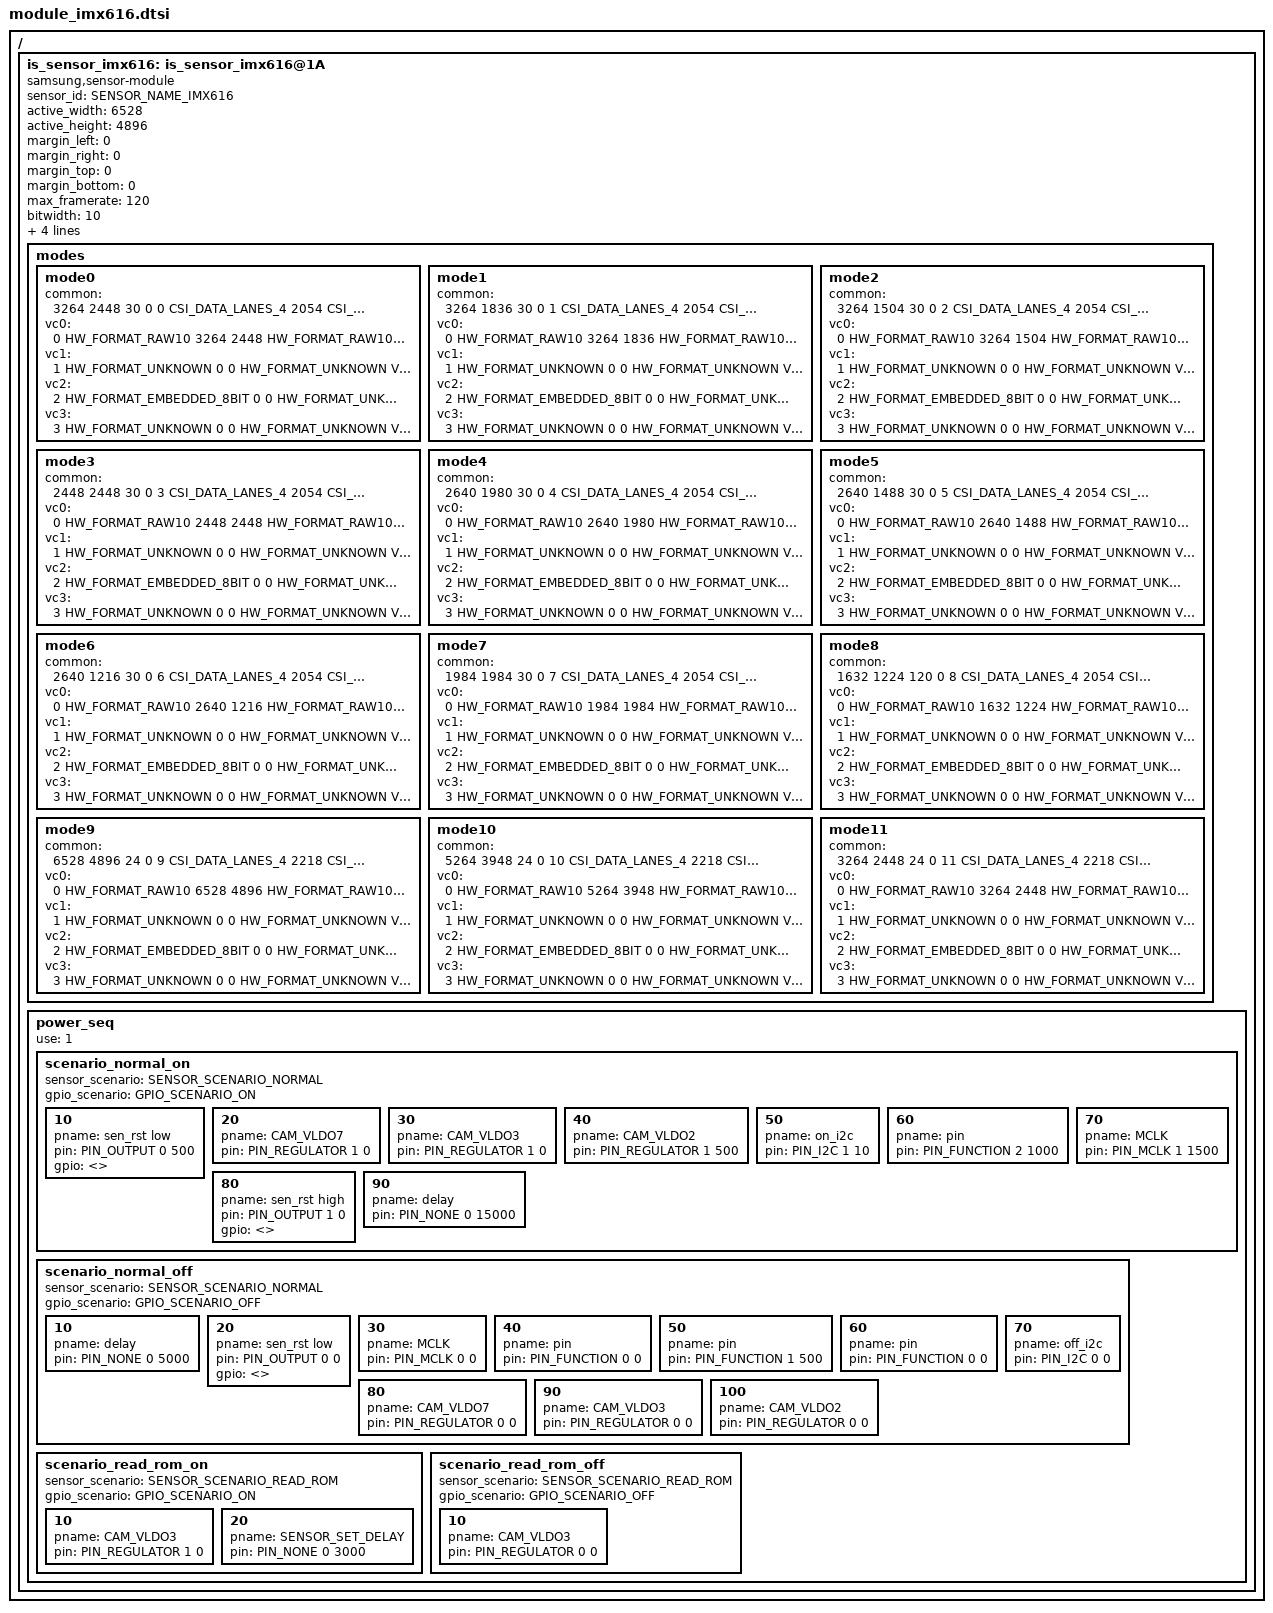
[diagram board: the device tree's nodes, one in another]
/*
 * SAMSUNG EXYNOSxxxx board camera device tree source
 *
 * Copyright (c) 2019 Samsung Electronics Co., Ltd.
 *		http://www.samsung.com
 *
 * This program is free software; you can redistribute it and/or modify
 * it under the terms of the GNU General Public License version 2 as
 * published by the Free Software Foundation.
 */

#include <dt-bindings/camera/exynos_is_dt.h>

/ {
	fragment@camera {
		target-path = "/";
		__overlay__ {
			is_sensor_imx616: is_sensor_imx616@1A {
				compatible = "samsung,sensor-module";

				/* common */
				sensor_id = <SENSOR_NAME_IMX616>;
				active_width = <6528>;
				active_height = <4896>;
				margin_left = <0>;
				margin_right = <0>;
				margin_top = <0>;
				margin_bottom = <0>;
				max_framerate = <120>;
				bitwidth = <10>;
				use_retention_mode = <SENSOR_RETENTION_INACTIVE>;
				sensor_maker = "SONY";
				sensor_name = "IMX616";
				setfile_name = "setfile_imx616.bin";

				status = "okay";

				/*
				 * [Mode Information]
				 *
				 * Reference File : IMX616-AAJH5_SAM-DPHY_26MHz_RegisterSetting_ver6.00-8.20_b2_190610.xlsx
				 *
				 * -. Global Setting -
				 *
				 * -. 2x2 BIN For Single Still Preview / Capture -
				 *    [ 0 ] REG_H : 2x2 Binning 3264x2448 30fps    : Single Still Preview (4:3)    ,  MIPI lane: 4, MIPI data rate(Mbps/lane): 2054
				 *    [ 1 ] REG_I : 2x2 Binning 3264x1836 30fps    : Single Still Preview (16:9)    ,  MIPI lane: 4, MIPI data rate(Mbps/lane): 2054
				 *    [ 2 ] REG_J : 2x2 Binning 3264x1504 30fps    : Single Still Preview (19.5:9)    ,  MIPI lane: 4, MIPI data rate(Mbps/lane): 2054
				 *    [ 3 ] REG_N : 2x2 Binning 2448x2448 30fps    : Single Still Preview (1:1)    ,  MIPI lane: 4, MIPI data rate(Mbps/lane): 2054
				 *
				 * -. 68ì2x2 BIN For Single Still Preview / Capture -
				 *    [ 4 ] REG_K : 2x2 Binning 2640x1980 30fps    : Single Still Preview (4:3)    ,  MIPI lane: 4, MIPI data rate(Mbps/lane): 2054
				 *    [ 5 ] REG_L : 2x2 Binning 2640x1448 30fps    : Single Still Preview (16:9)   ,  MIPI lane: 4, MIPI data rate(Mbps/lane): 2054
				 *    [ 6 ] REG_M : 2x2 Binning 2640x1216 30fps    : Single Still Preview (19.5:9)    ,  MIPI lane: 4, MIPI data rate(Mbps/lane): 2054
				 *    [ 7 ] REG_O : 2x2 Binning 1984x1984 30fps    : Single Still Preview (1:1)    ,  MIPI lane: 4, MIPI data rate(Mbps/lane): 2054
				 *
				 * -. 2x2 BIN H2V2 For FastAE
				 *    [ 8 ] REG_R : 2x2 Binning 1632x1224 120fps	 : FAST AE (4:3)	,  MIPI lane: 4, MIPI data rate(Mbps/lane): 2054
				 *
				 * -. FULL Remosaic For Single Still Remosaic Capture -
				 *    [ 9 ] REG_F  : Full Remosaic 6528x4896 24fps		 : Single Still Remosaic Capture (4:3) , MIPI lane: 4, MIPI data rate(Mbps/lane): 2218
				 *
				 * -. 68ìFULL Remosaic For Single Still Remosaic Capture -
				 *    [ 10 ] REG_G : Full Remosaic 5264x3948 24fps		 : Single Still Remosaic Capture (4:3) , MIPI lane: 4, MIPI data rate(Mbps/lane): 2218
				 *
				 * -. QBC HDR
				 *    [ 11 ] REG_S : QBC HDR 3264x2448 24fps	   : Single Still Preview (4:3)    ,  MIPI lane: 4, MIPI data rate(Mbps/lane): 2218
				 */

				/* sensor modes */
				modes {
						/* common = <width, height, fps, settle, mode, lane, speed, interleave, lrte, pd_mode> */
						/* vcX = <map, hwformat, width, height, hwformat, type, width, height> */

					/* 0 : 2X2BIN_3264x2448_30FPS */
					mode0 {
						common = <3264 2448 30 0 0 CSI_DATA_LANES_4 2054 CSI_MODE_DT_ONLY LRTE_DISABLE PD_NONE EX_NONE>;
						vc0 = </* in */ 0 HW_FORMAT_RAW10 3264 2448	/* out */ HW_FORMAT_RAW10 VC_NOTHING 0 0>;
						vc1 = </* in */ 1 HW_FORMAT_UNKNOWN 0 0		/* out */ HW_FORMAT_UNKNOWN VC_NOTHING 0 0>;
						vc2 = </* in */ 2 HW_FORMAT_EMBEDDED_8BIT 0 0	/* out */ HW_FORMAT_UNKNOWN VC_NOTHING 0 0>;
						vc3 = </* in */ 3 HW_FORMAT_UNKNOWN 0 0		/* out */ HW_FORMAT_UNKNOWN VC_NOTHING 0 0>;
					};
					/* 1 : 2X2BIN_3264x1836_30FPS */
					mode1 {
						common = <3264 1836 30 0 1 CSI_DATA_LANES_4 2054 CSI_MODE_DT_ONLY LRTE_DISABLE PD_NONE EX_NONE>;
						vc0 = </* in */ 0 HW_FORMAT_RAW10 3264 1836	/* out */ HW_FORMAT_RAW10 VC_NOTHING 0 0>;
						vc1 = </* in */ 1 HW_FORMAT_UNKNOWN 0 0		/* out */ HW_FORMAT_UNKNOWN VC_NOTHING 0 0>;
						vc2 = </* in */ 2 HW_FORMAT_EMBEDDED_8BIT 0 0	/* out */ HW_FORMAT_UNKNOWN VC_NOTHING 0 0>;
						vc3 = </* in */ 3 HW_FORMAT_UNKNOWN 0 0		/* out */ HW_FORMAT_UNKNOWN VC_NOTHING 0 0>;
					};
					/* 2 : 2X2BIN_3264x1504_30FPS */
					mode2 {
						common = <3264 1504 30 0 2 CSI_DATA_LANES_4 2054 CSI_MODE_DT_ONLY LRTE_DISABLE PD_NONE EX_NONE>;
						vc0 = </* in */ 0 HW_FORMAT_RAW10 3264 1504	/* out */ HW_FORMAT_RAW10 VC_NOTHING 0 0>;
						vc1 = </* in */ 1 HW_FORMAT_UNKNOWN 0 0		/* out */ HW_FORMAT_UNKNOWN VC_NOTHING 0 0>;
						vc2 = </* in */ 2 HW_FORMAT_EMBEDDED_8BIT 0 0	/* out */ HW_FORMAT_UNKNOWN VC_NOTHING 0 0>;
						vc3 = </* in */ 3 HW_FORMAT_UNKNOWN 0 0		/* out */ HW_FORMAT_UNKNOWN VC_NOTHING 0 0>;
					};
					/* 3: 2X2BIN_2448x2448_30FPS */
					mode3 {
						common = <2448 2448 30 0 3 CSI_DATA_LANES_4 2054 CSI_MODE_DT_ONLY LRTE_DISABLE PD_NONE EX_NONE>;
						vc0 = </* in */ 0 HW_FORMAT_RAW10 2448 2448	/* out */ HW_FORMAT_RAW10 VC_NOTHING 0 0>;
						vc1 = </* in */ 1 HW_FORMAT_UNKNOWN 0 0		/* out */ HW_FORMAT_UNKNOWN VC_NOTHING 0 0>;
						vc2 = </* in */ 2 HW_FORMAT_EMBEDDED_8BIT 0 0	/* out */ HW_FORMAT_UNKNOWN VC_NOTHING 0 0>;
						vc3 = </* in */ 3 HW_FORMAT_UNKNOWN 0 0		/* out */ HW_FORMAT_UNKNOWN VC_NOTHING 0 0>;
					};
					/* 4 : 68ìCrop 2X2BIN_2640x1980_30FPS */
					mode4 {
						common = <2640 1980 30 0 4 CSI_DATA_LANES_4 2054 CSI_MODE_DT_ONLY LRTE_DISABLE PD_NONE EX_NONE>;
						vc0 = </* in */ 0 HW_FORMAT_RAW10 2640 1980	/* out */ HW_FORMAT_RAW10 VC_NOTHING 0 0>;
						vc1 = </* in */ 1 HW_FORMAT_UNKNOWN 0 0		/* out */ HW_FORMAT_UNKNOWN VC_NOTHING 0 0>;
						vc2 = </* in */ 2 HW_FORMAT_EMBEDDED_8BIT 0 0	/* out */ HW_FORMAT_UNKNOWN VC_NOTHING 0 0>;
						vc3 = </* in */ 3 HW_FORMAT_UNKNOWN 0 0		/* out */ HW_FORMAT_UNKNOWN VC_NOTHING 0 0>;
					};
					/* 5 : 68ìCrop 2X2BIN_2640x1488_30FPS */
					mode5 {
						common = <2640 1488 30 0 5 CSI_DATA_LANES_4 2054 CSI_MODE_DT_ONLY LRTE_DISABLE PD_NONE EX_NONE>;
						vc0 = </* in */ 0 HW_FORMAT_RAW10 2640 1488	/* out */ HW_FORMAT_RAW10 VC_NOTHING 0 0>;
						vc1 = </* in */ 1 HW_FORMAT_UNKNOWN 0 0		/* out */ HW_FORMAT_UNKNOWN VC_NOTHING 0 0>;
						vc2 = </* in */ 2 HW_FORMAT_EMBEDDED_8BIT 0 0	/* out */ HW_FORMAT_UNKNOWN VC_NOTHING 0 0>;
						vc3 = </* in */ 3 HW_FORMAT_UNKNOWN 0 0		/* out */ HW_FORMAT_UNKNOWN VC_NOTHING 0 0>;
					};
					/* 6 : 68ìCrop 2X2BIN_2640x1216_30FPS */
					mode6 {
						common = <2640 1216 30 0 6 CSI_DATA_LANES_4 2054 CSI_MODE_DT_ONLY LRTE_DISABLE PD_NONE EX_NONE>;
						vc0 = </* in */ 0 HW_FORMAT_RAW10 2640 1216	/* out */ HW_FORMAT_RAW10 VC_NOTHING 0 0>;
						vc1 = </* in */ 1 HW_FORMAT_UNKNOWN 0 0		/* out */ HW_FORMAT_UNKNOWN VC_NOTHING 0 0>;
						vc2 = </* in */ 2 HW_FORMAT_EMBEDDED_8BIT 0 0	/* out */ HW_FORMAT_UNKNOWN VC_NOTHING 0 0>;
						vc3 = </* in */ 3 HW_FORMAT_UNKNOWN 0 0		/* out */ HW_FORMAT_UNKNOWN VC_NOTHING 0 0>;
					};
					/* 7 : 68ìCrop  2X2BIN_1984x1984_30FPS*/
					mode7 {
						common = <1984 1984 30 0 7 CSI_DATA_LANES_4 2054 CSI_MODE_DT_ONLY LRTE_DISABLE PD_NONE EX_NONE>;
						vc0 = </* in */ 0 HW_FORMAT_RAW10 1984 1984	/* out */ HW_FORMAT_RAW10 VC_NOTHING 0 0>;
						vc1 = </* in */ 1 HW_FORMAT_UNKNOWN 0 0		/* out */ HW_FORMAT_UNKNOWN VC_NOTHING 0 0>;
						vc2 = </* in */ 2 HW_FORMAT_EMBEDDED_8BIT 0 0	/* out */ HW_FORMAT_UNKNOWN VC_NOTHING 0 0>;
						vc3 = </* in */ 3 HW_FORMAT_UNKNOWN 0 0		/* out */ HW_FORMAT_UNKNOWN VC_NOTHING 0 0>;
					};
					/* 8 : H2V2_1632x1224_120FPS */
					mode8 {
						common = <1632 1224 120 0 8 CSI_DATA_LANES_4 2054 CSI_MODE_DT_ONLY LRTE_DISABLE PD_NONE EX_NONE>;
						vc0 = </* in */ 0 HW_FORMAT_RAW10 1632 1224	/* out */ HW_FORMAT_RAW10 VC_NOTHING 0 0>;
						vc1 = </* in */ 1 HW_FORMAT_UNKNOWN 0 0		/* out */ HW_FORMAT_UNKNOWN VC_NOTHING 0 0>;
						vc2 = </* in */ 2 HW_FORMAT_EMBEDDED_8BIT 0 0	/* out */ HW_FORMAT_UNKNOWN VC_NOTHING 0 0>;
						vc3 = </* in */ 3 HW_FORMAT_UNKNOWN 0 0		/* out */ HW_FORMAT_UNKNOWN VC_NOTHING 0 0>;
					};
					/* 9 : REMOSAIC_6528x4896_24FPS */
					mode9 {
						common = <6528 4896 24 0 9 CSI_DATA_LANES_4 2218 CSI_MODE_DT_ONLY LRTE_DISABLE PD_NONE EX_NONE>;
						vc0 = </* in */ 0 HW_FORMAT_RAW10 6528 4896	/* out */ HW_FORMAT_RAW10 VC_NOTHING 0 0>;
						vc1 = </* in */ 1 HW_FORMAT_UNKNOWN 0 0		/* out */ HW_FORMAT_UNKNOWN VC_NOTHING 0 0>;
						vc2 = </* in */ 2 HW_FORMAT_EMBEDDED_8BIT 0 0	/* out */ HW_FORMAT_UNKNOWN VC_NOTHING 0 0>;
						vc3 = </* in */ 3 HW_FORMAT_UNKNOWN 0 0		/* out */ HW_FORMAT_UNKNOWN VC_NOTHING 0 0>;
					};
					/* 10 : 68ìCrop REMOSAIC_5264x3948_24FPS */
					mode10 {
						common = <5264 3948 24 0 10 CSI_DATA_LANES_4 2218 CSI_MODE_DT_ONLY LRTE_DISABLE PD_NONE EX_NONE>;
						vc0 = </* in */ 0 HW_FORMAT_RAW10 5264 3948	/* out */ HW_FORMAT_RAW10 VC_NOTHING 0 0>;
						vc1 = </* in */ 1 HW_FORMAT_UNKNOWN 0 0		/* out */ HW_FORMAT_UNKNOWN VC_NOTHING 0 0>;
						vc2 = </* in */ 2 HW_FORMAT_EMBEDDED_8BIT 0 0	/* out */ HW_FORMAT_UNKNOWN VC_NOTHING 0 0>;
						vc3 = </* in */ 3 HW_FORMAT_UNKNOWN 0 0		/* out */ HW_FORMAT_UNKNOWN VC_NOTHING 0 0>;
					};
					/* 11 : QBCHDR_3264x2448_24FPS */
					mode11 {
						common = <3264 2448 24 0 11 CSI_DATA_LANES_4 2218 CSI_MODE_DT_ONLY LRTE_DISABLE PD_NONE EX_3DHDR>;
						vc0 = </* in */ 0 HW_FORMAT_RAW10 3264 2448	/* out */ HW_FORMAT_RAW10 VC_NOTHING 0 0>;
						vc1 = </* in */ 1 HW_FORMAT_UNKNOWN 0 0		/* out */ HW_FORMAT_UNKNOWN VC_NOTHING 0 0>;
						vc2 = </* in */ 2 HW_FORMAT_EMBEDDED_8BIT 0 0	/* out */ HW_FORMAT_UNKNOWN VC_NOTHING 0 0>;
						vc3 = </* in */ 3 HW_FORMAT_UNKNOWN 0 0		/* out */ HW_FORMAT_UNKNOWN VC_NOTHING 0 0>;
					};
				};

				power_seq {
					use = <1>;
					scenario_normal_on {
						sensor_scenario = <SENSOR_SCENARIO_NORMAL>;
						gpio_scenario = <GPIO_SCENARIO_ON>;

						/* A start node number should be over the 10 for reserved number 0~9. */
						/* pname = "name"; pin = <act value dealy voltage>; gpio = <gpx# # 0x1>; */
						10 { pname = "sen_rst low"; pin = <PIN_OUTPUT 0 500>; gpio = <>; };
						20 { pname = "CAM_VLDO7"; pin = <PIN_REGULATOR 1 0>; }; /* IMX616_AVDD 2.8V */
						30 { pname = "CAM_VLDO3"; pin = <PIN_REGULATOR 1 0>; }; /* IMX616_IOVDD 1.8V */
						40 { pname = "CAM_VLDO2"; pin = <PIN_REGULATOR 1 500>; }; /* IMX616_DVDD 1.05V */
						50 { pname = "on_i2c"; pin = <PIN_I2C 1 10>; };
						60 { pname = "pin"; pin = <PIN_FUNCTION 2 1000>; };
						70 { pname = "MCLK"; pin = <PIN_MCLK 1 1500>; };
						80 { pname = "sen_rst high"; pin = <PIN_OUTPUT 1 0>; gpio = <>; };
						90 { pname = "delay"; pin = <PIN_NONE 0 15000>; };
					};

					scenario_normal_off {
						sensor_scenario = <SENSOR_SCENARIO_NORMAL>;
						gpio_scenario = <GPIO_SCENARIO_OFF>;

						/* A start node number should be over the 10 for reserved number 0~9. */
						/* pname = "name"; pin = <act value dealy voltage>; gpio = <gpx# # 0x1>; */
						10 { pname = "delay"; pin = <PIN_NONE 0 5000>; };
						20 { pname = "sen_rst low"; pin = <PIN_OUTPUT 0 0>; gpio = <>; };
						30 { pname = "MCLK"; pin = <PIN_MCLK 0 0>; };
						40 { pname = "pin"; pin = <PIN_FUNCTION 0 0>; };
						50 { pname = "pin"; pin = <PIN_FUNCTION 1 500>; };
						60 { pname = "pin"; pin = <PIN_FUNCTION 0 0>; };
						70 { pname = "off_i2c"; pin = <PIN_I2C 0 0>; };
						80 { pname = "CAM_VLDO7"; pin = <PIN_REGULATOR 0 0>; }; /* IMX616_AVDD 2.8V */
						90 { pname = "CAM_VLDO3"; pin = <PIN_REGULATOR 0 0>; }; /* IMX616_IOVDD 1.8V */
						100 { pname = "CAM_VLDO2"; pin = <PIN_REGULATOR 0 0>; }; /* IMX616_DVDD 1.05V */
					};

					scenario_read_rom_on {
						sensor_scenario = <SENSOR_SCENARIO_READ_ROM>;
						gpio_scenario = <GPIO_SCENARIO_ON>;

						/* A start node number should be over the 10 for reserved number 0~9. */
						/* pname = "name"; pin = <act value dealy voltage>; gpio = <gpx# # 0x1>; */
						10 { pname = "CAM_VLDO3"; pin = <PIN_REGULATOR 1 0>; }; /* IMX616_IOVDD 1.8V */
						20 { pname = "SENSOR_SET_DELAY"; pin = <PIN_NONE 0 3000>; };
					};

					scenario_read_rom_off {
						sensor_scenario = <SENSOR_SCENARIO_READ_ROM>;
						gpio_scenario = <GPIO_SCENARIO_OFF>;

						/* A start node number should be over the 10 for reserved number 0~9. */
						/* pname = "name"; pin = <act value dealy voltage>; gpio = <gpx# # 0x1>; */
						10 { pname = "CAM_VLDO3"; pin = <PIN_REGULATOR 0 0>; }; /* IMX616_IOVDD 1.8V */
					};
				};
			};
		}; /* end of __overlay__ */
	}; /* end of fragment */
}; /* end of root */
